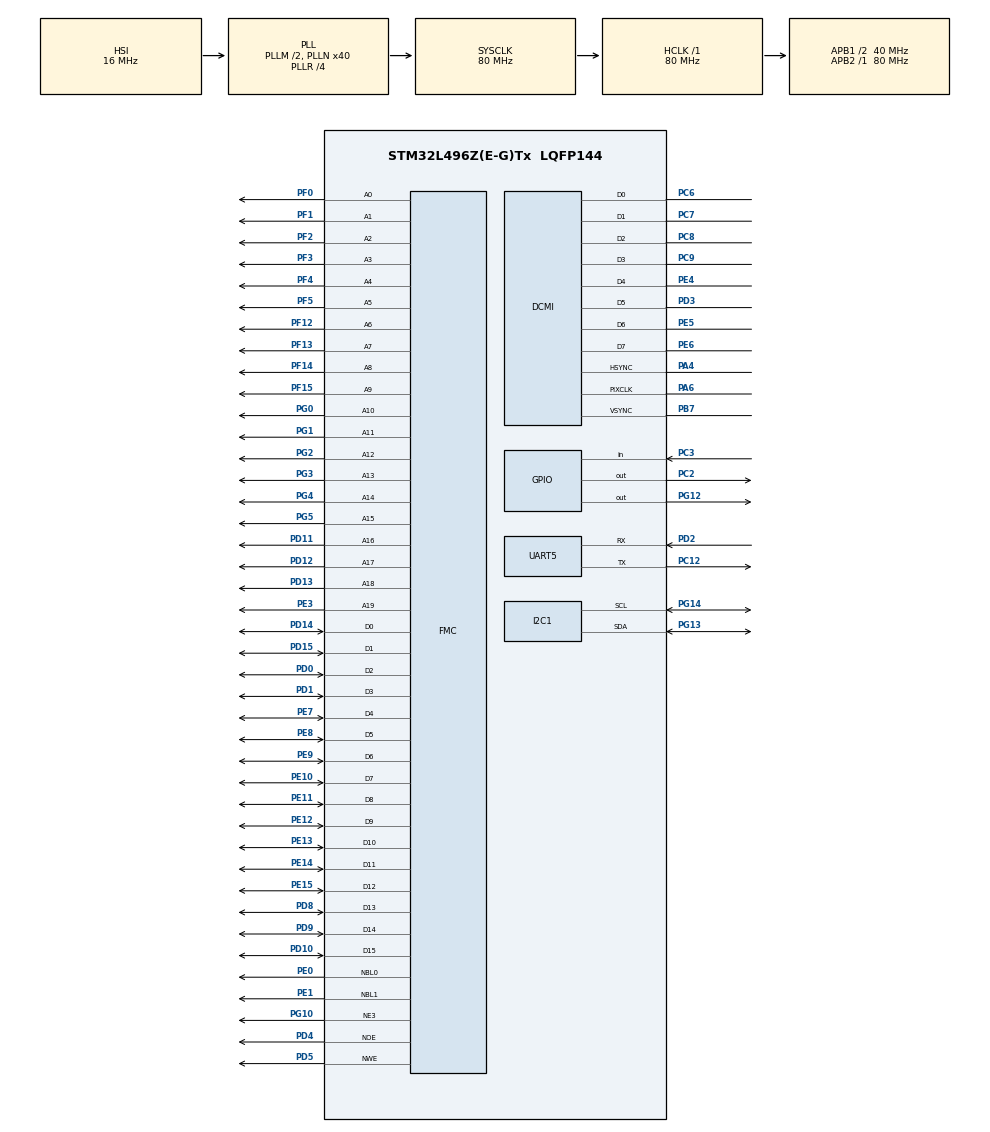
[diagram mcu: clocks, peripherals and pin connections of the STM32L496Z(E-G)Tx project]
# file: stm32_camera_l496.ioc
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Dma.DCMI.0.Direction=DMA_PERIPH_TO_MEMORY
Dma.DCMI.0.Instance=DMA2_Channel5
Dma.DCMI.0.MemDataAlignment=DMA_MDATAALIGN_WORD
Dma.DCMI.0.MemInc=DMA_MINC_ENABLE
Dma.DCMI.0.Mode=DMA_CIRCULAR
Dma.DCMI.0.PeriphDataAlignment=DMA_PDATAALIGN_WORD
Dma.DCMI.0.PeriphInc=DMA_PINC_DISABLE
Dma.DCMI.0.Priority=DMA_PRIORITY_HIGH
Dma.MEMTOMEM.1.Direction=DMA_MEMORY_TO_MEMORY
Dma.MEMTOMEM.1.Instance=DMA1_Channel1
Dma.MEMTOMEM.1.MemDataAlignment=DMA_MDATAALIGN_WORD
Dma.MEMTOMEM.1.MemInc=DMA_MINC_ENABLE
Dma.MEMTOMEM.1.Mode=DMA_NORMAL
Dma.MEMTOMEM.1.PeriphDataAlignment=DMA_PDATAALIGN_WORD
Dma.MEMTOMEM.1.PeriphInc=DMA_PINC_ENABLE
Dma.MEMTOMEM.1.Priority=DMA_PRIORITY_LOW
Dma.Request0=DCMI
Dma.Request1=MEMTOMEM
Dma.Request2=UART5_TX
Dma.UART5_TX.2.Direction=DMA_MEMORY_TO_PERIPH
Dma.UART5_TX.2.Instance=DMA2_Channel1
Dma.UART5_TX.2.MemDataAlignment=DMA_MDATAALIGN_BYTE
Dma.UART5_TX.2.MemInc=DMA_MINC_ENABLE
Dma.UART5_TX.2.Mode=DMA_NORMAL
Dma.UART5_TX.2.PeriphDataAlignment=DMA_PDATAALIGN_BYTE
Dma.UART5_TX.2.PeriphInc=DMA_PINC_DISABLE
Dma.UART5_TX.2.Priority=DMA_PRIORITY_LOW
FMC.AddressSetupTime1=12
FMC.DataSetupTime1=6
FMC.ExtendedAddressSetupTime1=0
FMC.ExtendedDataSetupTime1=6
FMC.ExtendedMode1=FMC_EXTENDED_MODE_ENABLE
FMC.WriteOperation1=FMC_WRITE_OPERATION_ENABLE
I2C1.NoStretchMode=I2C_NOSTRETCH_ENABLE
I2C1.Timing=0x00909BEB
Mcu.Family=STM32L4
Mcu.Name=STM32L496Z(E-G)Tx
Mcu.Package=LQFP144
NVIC.DCMI_IRQn=true\:0\:0\:false\:false\:true\:true\:true
NVIC.DMA2_Channel1_IRQn=true\:0\:0\:false\:false\:true\:false\:true
NVIC.DMA2_Channel5_IRQn=true\:0\:0\:false\:false\:true\:false\:true
NVIC.PriorityGroup=NVIC_PRIORITYGROUP_4
NVIC.UART5_IRQn=true\:0\:0\:false\:false\:true\:true\:true
PA4.Mode=Slave_8_bits_External_Synchro
PA4.Signal=DCMI_HSYNC
PA6.Mode=Slave_8_bits_External_Synchro
PA6.Signal=DCMI_PIXCLK
PB7.Mode=Slave_8_bits_External_Synchro
PB7.Signal=DCMI_VSYNC
PC12.Mode=Asynchronous
PC12.Signal=UART5_TX
PC2.GPIO_Speed=GPIO_SPEED_FREQ_HIGH
PC2.Signal=GPIO_Output
PC3.GPIO_PuPd=GPIO_NOPULL
PC3.Signal=GPIO_Input
PC6.Mode=Slave_8_bits_External_Synchro
PC6.Signal=DCMI_D0
PC7.Mode=Slave_8_bits_External_Synchro
PC7.Signal=DCMI_D1
PC8.Mode=Slave_8_bits_External_Synchro
PC8.Signal=DCMI_D2
PC9.Mode=Slave_8_bits_External_Synchro
PC9.Signal=DCMI_D3
PD0.Signal=FMC_D2_DA2
PD1.Signal=FMC_D3_DA3
PD10.Signal=FMC_D15_DA15
PD11.Signal=FMC_A16_CLE
PD12.Signal=FMC_A17_ALE
PD13.Signal=FMC_A18
PD14.Signal=FMC_D0_DA0
PD15.Signal=FMC_D1_DA1
PD2.Mode=Asynchronous
PD2.Signal=UART5_RX
PD3.Mode=Slave_8_bits_External_Synchro
PD3.Signal=DCMI_D5
PD4.Signal=FMC_NOE
PD5.Signal=FMC_NWE
PD8.Signal=FMC_D13_DA13
PD9.Signal=FMC_D14_DA14
PE0.Signal=FMC_NBL0
PE1.Signal=FMC_NBL1
PE10.Signal=FMC_D7_DA7
PE11.Signal=FMC_D8_DA8
PE12.Signal=FMC_D9_DA9
PE13.Signal=FMC_D10_DA10
PE14.Signal=FMC_D11_DA11
PE15.Signal=FMC_D12_DA12
PE3.Signal=FMC_A19
PE4.Mode=Slave_8_bits_External_Synchro
PE4.Signal=DCMI_D4
PE5.Mode=Slave_8_bits_External_Synchro
PE5.Signal=DCMI_D6
PE6.Mode=Slave_8_bits_External_Synchro
PE6.Signal=DCMI_D7
PE7.Signal=FMC_D4_DA4
PE8.Signal=FMC_D5_DA5
PE9.Signal=FMC_D6_DA6
PF0.Signal=FMC_A0
PF1.Signal=FMC_A1
PF12.Signal=FMC_A6
PF13.Signal=FMC_A7
PF14.Signal=FMC_A8
PF15.Signal=FMC_A9
PF2.Signal=FMC_A2
PF3.Signal=FMC_A3
PF4.Signal=FMC_A4
PF5.Signal=FMC_A5
PG0.Signal=FMC_A10
PG1.Signal=FMC_A11
PG10.Mode=NorPsramChipSelect3_1
PG10.Signal=FMC_NE3
PG12.GPIO_Speed=GPIO_SPEED_FREQ_HIGH
PG12.PinState=GPIO_PIN_SET
PG12.Signal=GPIO_Output
PG13.Mode=I2C
PG13.Signal=I2C1_SDA
PG14.Mode=I2C
PG14.Signal=I2C1_SCL
PG2.Signal=FMC_A12
PG3.Signal=FMC_A13
PG4.Signal=FMC_A14
PG5.Signal=FMC_A15
ProjectManager.HeapSize=0x200
ProjectManager.StackSize=0x400
ProjectManager.TargetToolchain=Makefile
RCC.48MHZClocksFreq_Value=24000000
RCC.ADCFreq_Value=96000000
RCC.AHBFreq_Value=80000000
RCC.APB1CLKDivider=RCC_HCLK_DIV2
RCC.APB1Freq_Value=40000000
RCC.APB1TimFreq_Value=80000000
RCC.APB2Freq_Value=80000000
RCC.APB2TimFreq_Value=80000000
RCC.CortexFreq_Value=80000000
RCC.HCLKFreq_Value=80000000
RCC.HSE_VALUE=8000000
RCC.HSI48_VALUE=48000000
RCC.HSI_VALUE=16000000
RCC.LSE_VALUE=32768
RCC.MSI_VALUE=4000000
RCC.PLLM=2
RCC.PLLMUL=RCC_PLL_MUL9
RCC.PLLN=40
RCC.PLLR=RCC_PLLR_DIV4
RCC.PLLSAI1N=24
RCC.PLLSourceVirtual=RCC_PLLSOURCE_HSI
RCC.PRESCALERUSB=RCC_USBCLKSOURCE_PLL_DIV1_5
RCC.SYSCLKFreq_VALUE=80000000
RCC.SYSCLKSource=RCC_SYSCLKSOURCE_PLLCLK
RCC.SYSCLKSourceVirtual=RCC_SYSCLKSOURCE_PLLCLK
RCC.USBFreq_Value=96000000
RCC.VCOOutputFreq_Value=320000000
SH.FMC_A0.0=FMC_A0,20b-a1
SH.FMC_A1.0=FMC_A1,20b-a1
SH.FMC_A10.0=FMC_A10,20b-a1
SH.FMC_A11.0=FMC_A11,20b-a1
SH.FMC_A12.0=FMC_A12,20b-a1
SH.FMC_A13.0=FMC_A13,20b-a1
SH.FMC_A14.0=FMC_A14,20b-a1
SH.FMC_A15.0=FMC_A15,20b-a1
SH.FMC_A16_CLE.0=FMC_A16,20b-a1
SH.FMC_A17_ALE.0=FMC_A17,20b-a1
SH.FMC_A18.0=FMC_A18,20b-a1
SH.FMC_A19.0=FMC_A19,20b-a1
SH.FMC_A2.0=FMC_A2,20b-a1
SH.FMC_A3.0=FMC_A3,20b-a1
SH.FMC_A4.0=FMC_A4,20b-a1
SH.FMC_A5.0=FMC_A5,20b-a1
SH.FMC_A6.0=FMC_A6,20b-a1
SH.FMC_A7.0=FMC_A7,20b-a1
SH.FMC_A8.0=FMC_A8,20b-a1
SH.FMC_A9.0=FMC_A9,20b-a1
SH.FMC_D0_DA0.0=FMC_D0,16b-d1
SH.FMC_D10_DA10.0=FMC_D10,16b-d1
SH.FMC_D11_DA11.0=FMC_D11,16b-d1
SH.FMC_D12_DA12.0=FMC_D12,16b-d1
SH.FMC_D13_DA13.0=FMC_D13,16b-d1
SH.FMC_D14_DA14.0=FMC_D14,16b-d1
SH.FMC_D15_DA15.0=FMC_D15,16b-d1
SH.FMC_D1_DA1.0=FMC_D1,16b-d1
SH.FMC_D2_DA2.0=FMC_D2,16b-d1
SH.FMC_D3_DA3.0=FMC_D3,16b-d1
SH.FMC_D4_DA4.0=FMC_D4,16b-d1
SH.FMC_D5_DA5.0=FMC_D5,16b-d1
SH.FMC_D6_DA6.0=FMC_D6,16b-d1
SH.FMC_D7_DA7.0=FMC_D7,16b-d1
SH.FMC_D8_DA8.0=FMC_D8,16b-d1
SH.FMC_D9_DA9.0=FMC_D9,16b-d1
SH.FMC_NBL0.0=FMC_NBL0,2ByteEnable1
SH.FMC_NBL1.0=FMC_NBL1,2ByteEnable1
SH.FMC_NOE.0=FMC_NOE,Sram1
SH.FMC_NWE.0=FMC_NWE,Sram1
VP_TIM1_VS_ClockSourceINT.Mode=Internal
board=NUCLEO-L496ZG

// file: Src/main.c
/* USER CODE BEGIN Header */
/**
 ******************************************************************************
 * @file           : main.c
 * @brief          : Main program body
 ******************************************************************************
 * @attention
 *
 * <h2><center>&copy; Copyright (c) 2019 STMicroelectronics.
 * All rights reserved.</center></h2>
 *
 * This software component is licensed by ST under BSD 3-Clause license,
 * the "License"; You may not use this file except in compliance with the
 * License. You may obtain a copy of the License at:
 *                        opensource.org/licenses/BSD-3-Clause
 *
 ******************************************************************************
 */
/* USER CODE END Header */

#include "main.h"

/* USER CODE BEGIN Includes */
#include "user_main.h"
#include "var_interface.h"

/* USER CODE END Includes */

DCMI_HandleTypeDef hdcmi;
DMA_HandleTypeDef hdma_dcmi;

I2C_HandleTypeDef hi2c1;

TIM_HandleTypeDef htim1;

UART_HandleTypeDef huart5;
DMA_HandleTypeDef hdma_uart5_tx;

DMA_HandleTypeDef hdma_memtomem_dma1_channel1;
SRAM_HandleTypeDef hsram1;

/* USER CODE BEGIN PV */
uint8_t image_data[IMAGE_SIZE] = { 0 };
int uart_complete = 0;

/* USER CODE END PV */

void SystemClock_Config(void);
static void MX_GPIO_Init(void);
static void MX_DMA_Init(void);
static void MX_DCMI_Init(void);
static void MX_I2C1_Init(void);
static void MX_UART5_Init(void);
static void MX_FMC_Init(void);
static void MX_TIM1_Init(void);

int main(void)
{

  /* MCU Configuration--------------------------------------------------------*/

  /* Reset of all peripherals, Initializes the Flash interface and the Systick. */
  HAL_Init();

  /* Configure the system clock */
  SystemClock_Config();

  /* Initialize all configured peripherals */
  MX_GPIO_Init();
  MX_DMA_Init();
  MX_DCMI_Init();
  MX_I2C1_Init();
  MX_UART5_Init();
  MX_FMC_Init();
  MX_TIM1_Init();
  /* USER CODE BEGIN 2 */
	user_code2();
	user_code3();

  /* USER CODE END 2 */

  /* Infinite loop */
  /* USER CODE BEGIN WHILE */
	while (1) {
		//user_code3();
    /* USER CODE END WHILE */

	}
}

void SystemClock_Config(void)
{
  RCC_OscInitTypeDef RCC_OscInitStruct = {0};
  RCC_ClkInitTypeDef RCC_ClkInitStruct = {0};
  RCC_PeriphCLKInitTypeDef PeriphClkInit = {0};

  /** Initializes the CPU, AHB and APB busses clocks
  */
  RCC_OscInitStruct.OscillatorType = RCC_OSCILLATORTYPE_HSI;
  RCC_OscInitStruct.HSIState = RCC_HSI_ON;
  RCC_OscInitStruct.HSICalibrationValue = RCC_HSICALIBRATION_DEFAULT;
  RCC_OscInitStruct.PLL.PLLState = RCC_PLL_ON;
  RCC_OscInitStruct.PLL.PLLSource = RCC_PLLSOURCE_HSI;
  RCC_OscInitStruct.PLL.PLLM = 2;
  RCC_OscInitStruct.PLL.PLLN = 40;
  RCC_OscInitStruct.PLL.PLLP = RCC_PLLP_DIV2;
  RCC_OscInitStruct.PLL.PLLQ = RCC_PLLQ_DIV2;
  RCC_OscInitStruct.PLL.PLLR = RCC_PLLR_DIV4;
  if (HAL_RCC_OscConfig(&RCC_OscInitStruct) != HAL_OK)
  {
    Error_Handler();
  }
  /** Initializes the CPU, AHB and APB busses clocks
  */
  RCC_ClkInitStruct.ClockType = RCC_CLOCKTYPE_HCLK|RCC_CLOCKTYPE_SYSCLK
                              |RCC_CLOCKTYPE_PCLK1|RCC_CLOCKTYPE_PCLK2;
  RCC_ClkInitStruct.SYSCLKSource = RCC_SYSCLKSOURCE_PLLCLK;
  RCC_ClkInitStruct.AHBCLKDivider = RCC_SYSCLK_DIV1;
  RCC_ClkInitStruct.APB1CLKDivider = RCC_HCLK_DIV2;
  RCC_ClkInitStruct.APB2CLKDivider = RCC_HCLK_DIV1;

  if (HAL_RCC_ClockConfig(&RCC_ClkInitStruct, FLASH_LATENCY_4) != HAL_OK)
  {
    Error_Handler();
  }
  PeriphClkInit.PeriphClockSelection = RCC_PERIPHCLK_UART5|RCC_PERIPHCLK_I2C1;
  PeriphClkInit.Uart5ClockSelection = RCC_UART5CLKSOURCE_PCLK1;
  PeriphClkInit.I2c1ClockSelection = RCC_I2C1CLKSOURCE_PCLK1;
  if (HAL_RCCEx_PeriphCLKConfig(&PeriphClkInit) != HAL_OK)
  {
    Error_Handler();
  }
  /** Configure the main internal regulator output voltage
  */
  if (HAL_PWREx_ControlVoltageScaling(PWR_REGULATOR_VOLTAGE_SCALE1) != HAL_OK)
  {
    Error_Handler();
  }
}

static void MX_DCMI_Init(void)
{

  hdcmi.Instance = DCMI;
  hdcmi.Init.SynchroMode = DCMI_SYNCHRO_HARDWARE;
  hdcmi.Init.PCKPolarity = DCMI_PCKPOLARITY_FALLING;
  hdcmi.Init.VSPolarity = DCMI_VSPOLARITY_LOW;
  hdcmi.Init.HSPolarity = DCMI_HSPOLARITY_LOW;
  hdcmi.Init.CaptureRate = DCMI_CR_ALL_FRAME;
  hdcmi.Init.ExtendedDataMode = DCMI_EXTEND_DATA_8B;
  hdcmi.Init.JPEGMode = DCMI_JPEG_DISABLE;
  hdcmi.Init.ByteSelectMode = DCMI_BSM_ALL;
  hdcmi.Init.ByteSelectStart = DCMI_OEBS_ODD;
  hdcmi.Init.LineSelectMode = DCMI_LSM_ALL;
  hdcmi.Init.LineSelectStart = DCMI_OELS_ODD;
  if (HAL_DCMI_Init(&hdcmi) != HAL_OK)
  {
    Error_Handler();
  }

}

static void MX_I2C1_Init(void)
{

  hi2c1.Instance = I2C1;
  hi2c1.Init.Timing = 0x00909BEB;
  hi2c1.Init.OwnAddress1 = 0;
  hi2c1.Init.AddressingMode = I2C_ADDRESSINGMODE_7BIT;
  hi2c1.Init.DualAddressMode = I2C_DUALADDRESS_DISABLE;
  hi2c1.Init.OwnAddress2 = 0;
  hi2c1.Init.OwnAddress2Masks = I2C_OA2_NOMASK;
  hi2c1.Init.GeneralCallMode = I2C_GENERALCALL_DISABLE;
  hi2c1.Init.NoStretchMode = I2C_NOSTRETCH_ENABLE;
  if (HAL_I2C_Init(&hi2c1) != HAL_OK)
  {
    Error_Handler();
  }
  /** Configure Analogue filter
  */
  if (HAL_I2CEx_ConfigAnalogFilter(&hi2c1, I2C_ANALOGFILTER_ENABLE) != HAL_OK)
  {
    Error_Handler();
  }
  /** Configure Digital filter
  */
  if (HAL_I2CEx_ConfigDigitalFilter(&hi2c1, 0) != HAL_OK)
  {
    Error_Handler();
  }

}

static void MX_TIM1_Init(void)
{

  TIM_ClockConfigTypeDef sClockSourceConfig = {0};
  TIM_MasterConfigTypeDef sMasterConfig = {0};

  htim1.Instance = TIM1;
  htim1.Init.Prescaler = 0;
  htim1.Init.CounterMode = TIM_COUNTERMODE_UP;
  htim1.Init.Period = 0;
  htim1.Init.ClockDivision = TIM_CLOCKDIVISION_DIV1;
  htim1.Init.RepetitionCounter = 0;
  htim1.Init.AutoReloadPreload = TIM_AUTORELOAD_PRELOAD_DISABLE;
  if (HAL_TIM_Base_Init(&htim1) != HAL_OK)
  {
    Error_Handler();
  }
  sClockSourceConfig.ClockSource = TIM_CLOCKSOURCE_INTERNAL;
  if (HAL_TIM_ConfigClockSource(&htim1, &sClockSourceConfig) != HAL_OK)
  {
    Error_Handler();
  }
  sMasterConfig.MasterOutputTrigger = TIM_TRGO_RESET;
  sMasterConfig.MasterOutputTrigger2 = TIM_TRGO2_RESET;
  sMasterConfig.MasterSlaveMode = TIM_MASTERSLAVEMODE_DISABLE;
  if (HAL_TIMEx_MasterConfigSynchronization(&htim1, &sMasterConfig) != HAL_OK)
  {
    Error_Handler();
  }

}

static void MX_UART5_Init(void)
{

  huart5.Instance = UART5;
  huart5.Init.BaudRate = 115200;
  huart5.Init.WordLength = UART_WORDLENGTH_8B;
  huart5.Init.StopBits = UART_STOPBITS_1;
  huart5.Init.Parity = UART_PARITY_NONE;
  huart5.Init.Mode = UART_MODE_TX_RX;
  huart5.Init.HwFlowCtl = UART_HWCONTROL_NONE;
  huart5.Init.OverSampling = UART_OVERSAMPLING_16;
  huart5.Init.OneBitSampling = UART_ONE_BIT_SAMPLE_DISABLE;
  huart5.AdvancedInit.AdvFeatureInit = UART_ADVFEATURE_NO_INIT;
  if (HAL_UART_Init(&huart5) != HAL_OK)
  {
    Error_Handler();
  }

}

static void MX_DMA_Init(void)
{

  /* DMA controller clock enable */
  __HAL_RCC_DMA2_CLK_ENABLE();
  __HAL_RCC_DMA1_CLK_ENABLE();

  /* Configure DMA request hdma_memtomem_dma1_channel1 on DMA1_Channel1 */
  hdma_memtomem_dma1_channel1.Instance = DMA1_Channel1;
  hdma_memtomem_dma1_channel1.Init.Request = DMA_REQUEST_0;
  hdma_memtomem_dma1_channel1.Init.Direction = DMA_MEMORY_TO_MEMORY;
  hdma_memtomem_dma1_channel1.Init.PeriphInc = DMA_PINC_ENABLE;
  hdma_memtomem_dma1_channel1.Init.MemInc = DMA_MINC_ENABLE;
  hdma_memtomem_dma1_channel1.Init.PeriphDataAlignment = DMA_PDATAALIGN_WORD;
  hdma_memtomem_dma1_channel1.Init.MemDataAlignment = DMA_MDATAALIGN_WORD;
  hdma_memtomem_dma1_channel1.Init.Mode = DMA_NORMAL;
  hdma_memtomem_dma1_channel1.Init.Priority = DMA_PRIORITY_LOW;
  if (HAL_DMA_Init(&hdma_memtomem_dma1_channel1) != HAL_OK)
  {
    Error_Handler( );
  }

  /* DMA interrupt init */
  /* DMA2_Channel1_IRQn interrupt configuration */
  HAL_NVIC_SetPriority(DMA2_Channel1_IRQn, 0, 0);
  HAL_NVIC_EnableIRQ(DMA2_Channel1_IRQn);
  /* DMA2_Channel5_IRQn interrupt configuration */
  HAL_NVIC_SetPriority(DMA2_Channel5_IRQn, 0, 0);
  HAL_NVIC_EnableIRQ(DMA2_Channel5_IRQn);

}

/* FMC initialization function */
static void MX_FMC_Init(void)
{

  FMC_NORSRAM_TimingTypeDef Timing = {0};
  FMC_NORSRAM_TimingTypeDef ExtTiming = {0};

  /** Perform the SRAM1 memory initialization sequence
  */
  hsram1.Instance = FMC_NORSRAM_DEVICE;
  hsram1.Extended = FMC_NORSRAM_EXTENDED_DEVICE;
  /* hsram1.Init */
  hsram1.Init.NSBank = FMC_NORSRAM_BANK3;
  hsram1.Init.DataAddressMux = FMC_DATA_ADDRESS_MUX_DISABLE;
  hsram1.Init.MemoryType = FMC_MEMORY_TYPE_SRAM;
  hsram1.Init.MemoryDataWidth = FMC_NORSRAM_MEM_BUS_WIDTH_16;
  hsram1.Init.BurstAccessMode = FMC_BURST_ACCESS_MODE_DISABLE;
  hsram1.Init.WaitSignalPolarity = FMC_WAIT_SIGNAL_POLARITY_LOW;
  hsram1.Init.WaitSignalActive = FMC_WAIT_TIMING_BEFORE_WS;
  hsram1.Init.WriteOperation = FMC_WRITE_OPERATION_ENABLE;
  hsram1.Init.WaitSignal = FMC_WAIT_SIGNAL_DISABLE;
  hsram1.Init.ExtendedMode = FMC_EXTENDED_MODE_ENABLE;
  hsram1.Init.AsynchronousWait = FMC_ASYNCHRONOUS_WAIT_DISABLE;
  hsram1.Init.WriteBurst = FMC_WRITE_BURST_DISABLE;
  hsram1.Init.ContinuousClock = FMC_CONTINUOUS_CLOCK_SYNC_ONLY;
  hsram1.Init.WriteFifo = FMC_WRITE_FIFO_ENABLE;
  hsram1.Init.PageSize = FMC_PAGE_SIZE_NONE;
  /* Timing */
  Timing.AddressSetupTime = 12;
  Timing.AddressHoldTime = 15;
  Timing.DataSetupTime = 6;
  Timing.BusTurnAroundDuration = 15;
  Timing.CLKDivision = 16;
  Timing.DataLatency = 17;
  Timing.AccessMode = FMC_ACCESS_MODE_A;
  /* ExtTiming */
  ExtTiming.AddressSetupTime = 0;
  ExtTiming.AddressHoldTime = 15;
  ExtTiming.DataSetupTime = 6;
  ExtTiming.BusTurnAroundDuration = 15;
  ExtTiming.CLKDivision = 16;
  ExtTiming.DataLatency = 17;
  ExtTiming.AccessMode = FMC_ACCESS_MODE_A;

  if (HAL_SRAM_Init(&hsram1, &Timing, &ExtTiming) != HAL_OK)
  {
    Error_Handler( );
  }

}

static void MX_GPIO_Init(void)
{
  GPIO_InitTypeDef GPIO_InitStruct = {0};

  /* GPIO Ports Clock Enable */
  __HAL_RCC_GPIOE_CLK_ENABLE();
  __HAL_RCC_GPIOF_CLK_ENABLE();
  __HAL_RCC_GPIOC_CLK_ENABLE();
  __HAL_RCC_GPIOA_CLK_ENABLE();
  __HAL_RCC_GPIOG_CLK_ENABLE();
  __HAL_RCC_GPIOD_CLK_ENABLE();
  HAL_PWREx_EnableVddIO2();
  __HAL_RCC_GPIOB_CLK_ENABLE();

  /*Configure GPIO pin Output Level */
  HAL_GPIO_WritePin(GPIOC, GPIO_PIN_2, GPIO_PIN_RESET);

  /*Configure GPIO pin Output Level */
  HAL_GPIO_WritePin(GPIOG, GPIO_PIN_12, GPIO_PIN_SET);

  /*Configure GPIO pin : PC2 */
  GPIO_InitStruct.Pin = GPIO_PIN_2;
  GPIO_InitStruct.Mode = GPIO_MODE_OUTPUT_PP;
  GPIO_InitStruct.Pull = GPIO_NOPULL;
  GPIO_InitStruct.Speed = GPIO_SPEED_FREQ_HIGH;
  HAL_GPIO_Init(GPIOC, &GPIO_InitStruct);

  /*Configure GPIO pin : PC3 */
  GPIO_InitStruct.Pin = GPIO_PIN_3;
  GPIO_InitStruct.Mode = GPIO_MODE_INPUT;
  GPIO_InitStruct.Pull = GPIO_NOPULL;
  HAL_GPIO_Init(GPIOC, &GPIO_InitStruct);

  /*Configure GPIO pin : PG12 */
  GPIO_InitStruct.Pin = GPIO_PIN_12;
  GPIO_InitStruct.Mode = GPIO_MODE_OUTPUT_PP;
  GPIO_InitStruct.Pull = GPIO_NOPULL;
  GPIO_InitStruct.Speed = GPIO_SPEED_FREQ_HIGH;
  HAL_GPIO_Init(GPIOG, &GPIO_InitStruct);

}

void Error_Handler(void)
{
}

/************************ (C) COPYRIGHT STMicroelectronics *****END OF FILE****/
